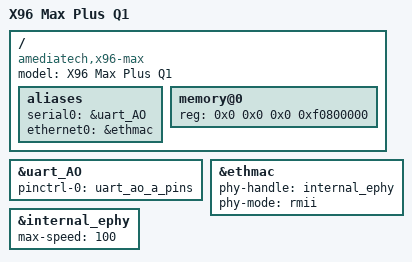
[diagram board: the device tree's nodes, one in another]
// SPDX-License-Identifier: (GPL-2.0+ OR MIT)
/*
 * Copyright (c) 2019 BayLibre SAS. All rights reserved.
 * Copyright (c) 2020 Christian Hewitt <christianshewitt@gmail.com>
 * Copyright (c) 2022 Flippy
 */

/dts-v1/;

#include "meson-sm1-x96-air.dts"

/ {
	compatible = "amediatech,x96-max", "amlogic,sm1";
	model = "X96 Max Plus Q1";

	aliases {
		serial0 = &uart_AO;
		ethernet0 = &ethmac;
	};

	memory@0 {
		device_type = "memory";
		reg = <0x0 0x0 0x0 0xf0800000>;
	};
};

&uart_AO {
	status = "okay";
	pinctrl-0 = <&uart_ao_a_pins>;
	pinctrl-names = "default";
};

&ethmac {
	status = "okay";
	phy-handle = <&internal_ephy>;
	phy-mode = "rmii";
};

&internal_ephy  {
	max-speed = <100>;
};
